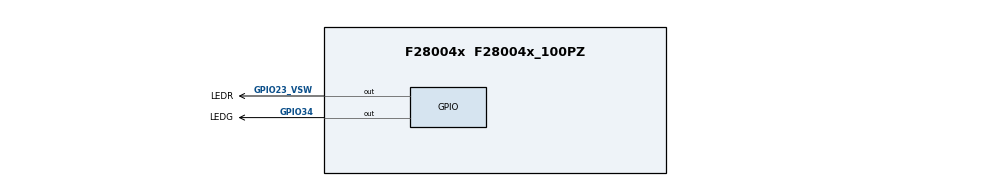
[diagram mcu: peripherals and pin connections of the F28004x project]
/**
 * @cliArgs --device "F28004x" --part "F28004x_100PZ" --package "F28004x_100PZ" --context "system" --product "C2000WARE@5.03.00.00"
 * @versions {"tool":"1.21.0+3721"}
 */

/**
 * Import the modules used in this configuration.
 */
const cla            = scripting.addModule("/driverlib/cla.js", {}, false);
const cla1           = cla.addInstance();
const device_support = scripting.addModule("/driverlib/device_support.js");
const gpio           = scripting.addModule("/driverlib/gpio.js", {}, false);
const gpio1          = gpio.addInstance();
const gpio2          = gpio.addInstance();
const memcfg         = scripting.addModule("/driverlib/memcfg.js");

/**
 * Write custom configuration values to the imported modules.
 */
cla1.enable_CLA_TASK_2                     = false;
cla1.enable_CLA_TASK_4                     = false;
cla1.enable_CLA_TASK_5                     = false;
cla1.enable_CLA_TASK_6                     = false;
cla1.enable_CLA_TASK_7                     = false;
cla1.enable_CLA_TASK_8                     = false;
cla1.enable_CLA_TASK_3                     = false;
cla1.name_CLA_TASK_1                       = "CLATaskCallback1";
cla1.cpuint_CLA_TASK_2                     = false;
cla1.cpuint_CLA_TASK_3                     = false;
cla1.cpuint_CLA_TASK_5                     = false;
cla1.cpuint_CLA_TASK_4                     = false;
cla1.cpuint_CLA_TASK_6                     = false;
cla1.cpuint_CLA_TASK_7                     = false;
cla1.cpuint_CLA_TASK_8                     = false;
cla1.$name                                 = "myCLA1";
cla1.intconfig_CLA_TASK_1.interruptHandler = "C28_CLA11_ISR";

gpio1.$name           = "LEDR";
gpio1.direction       = "GPIO_DIR_MODE_OUT";
gpio1.gpioPin.$assign = "GPIO23_VSW";

gpio2.$name           = "LEDG";
gpio2.direction       = "GPIO_DIR_MODE_OUT";
gpio2.gpioPin.$assign = "GPIO34";

memcfg.config_MEMCFG_SECT_LS1        = "CLA_data";
memcfg.init_MEMCFG_SECT_MSGCPUTOCLA1 = true;
memcfg.init_MEMCFG_SECT_MSGCLA1TOCPU = true;
memcfg.config_MEMCFG_SECT_LS2        = "CLA_data";
memcfg.config_MEMCFG_SECT_LS3        = "CLA_data";
